# B6x register map
Vendor: XiaoMan; Series: B6 SOC; File version: 20260307
CPU: CM0+ r0p0, little endian, no MPU, no FPU, 2 interrupt priority bits
Registers are 32-bit, read-write, reset 0x0 unless marked. A register's access mark holds for its fields unless they carry their own. Offsets are from the block's base; [hi:lo] are bit positions; 'fields as' and 'values as' point back to an identical list.

## UART1
Base 0x40023000
Same registers: UART2 0x40024000
0x00 RBR — Receiver Buffer Register
0x04 TBR — Transmit Buffer Register
0x08 BRR — Baud rate register
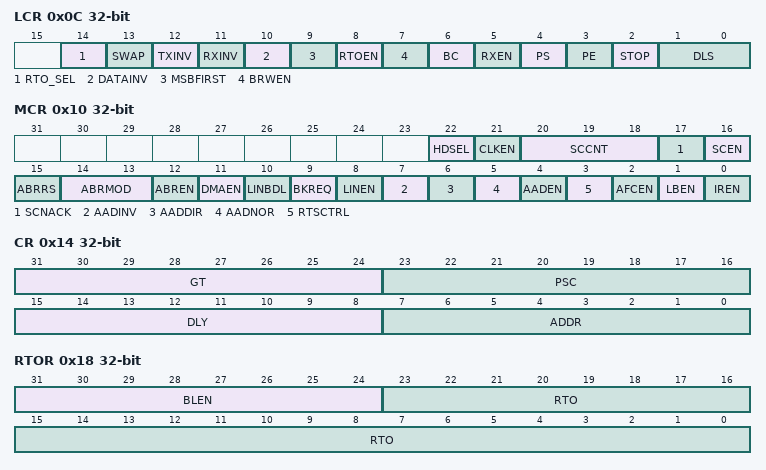
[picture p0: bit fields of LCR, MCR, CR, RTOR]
0x0C LCR — Line control register.
  [14] RTO_SEL — receiver timeout mode select: 0:CPU, 1:DMA
  [13] SWAP — Swap TX/RX pins
  [12] TXINV — TX pin active level inversion
  [11] RXINV — RX pin active level inversion
  [10] DATAINV — Binary data inversion
  [9] MSBFIRST — Most significant bit first
  [8] RTOEN — Receiver timeout enable
  [7] BRWEN — Baud rate register write enable
  [6] BC — Break control bit
  [5] RXEN — Receive enable
  [4] PS — Parity bit selection
  [3] PE — Parity bit enable
  [2] STOP — Stop bit
  [1:0] DLS — Data length selection
0x10 MCR — Mode control register
  [22] HDSEL — Half-duplex selection.
  [21] CLKEN — Clock enable.
  [20:18] SCCNT — Smartcard auto-retry count.
  [17] SCNACK — Smartcard NACK enable.
  [16] SCEN — Smartcard mode enable.
  [15] ABRRS — Auto baud rate detection restart.
  [14:13] ABRMOD — Auto baud rate mode.
  [12] ABREN — Auto baud rate enable.
  [11] DMAEN — DMA enable.
  [10] LINBDL
  [9] BKREQ — Break request.
  [8] LINEN — Lin mode enable.
  [7] AADINV — Automatic address detection invert.
  [6] AADDIR — Automatic address detection control enable.
  [5] AADNOR — Automatic address detection normal mode enable.
  [4] AADEN — Automatic address detection operation mode enable.
  [3] RTSCTRL — RTSn set control bit.
  [2] AFCEN — Auto flow control enable.
  [1] LBEN — LoopBack enable.
  [0] IREN — IrDA mode enable.
0x14 CR — Control register.
  [31:24] GT — Guard time value.
  [23:16] PSC — Prescaler value.
  [15:8] DLY — Delay value.
  [7:0] ADDR — Address match value.
0x18 RTOR — Receive timeout register.
  [31:24] BLEN — Block length.
  [23:0] RTO — Receive timeout value.
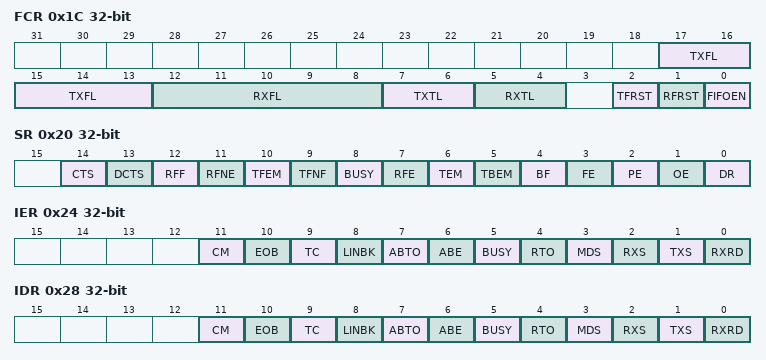
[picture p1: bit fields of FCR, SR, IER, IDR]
0x1C FCR — FIFO Control Register. Controls UART FIFO usage and modes.
  [17:13] TXFL — Transmit FIFO level.
  [12:8] RXFL — Receive FIFO level.
  [7:6] TXTL — Transmit FIFO trigger level.
  [5:4] RXTL — Receive FIFO trigger level. These two bits determine how many receiver UART FIFO characters must be written before an interrupt is activated.
    0=TRIGGER_LEVEL_0 (Trigger level 0 (1 character or 0x01).); 1=TRIGGER_LEVEL_1 (Trigger level 1 (4 characters or 0x04).); 2=TRIGGER_LEVEL_2 (Trigger level 2 (8 characters or 0x08).); 3=TRIGGER_LEVEL_3 (Trigger level 3 (14 characters or 0x0E).)
  [2] TFRST — Transmit FIFO reset.
    0=NO_IMPACT_ON_EITHER_ (No impact on either of UART FIFOs.); 1=CLEAR (Writing a logic 1 to FCR[2] will clear all bytes in UART TX FIFO, reset the pointer logic. This bit is self-clearing.)
  [1] RFRST — Receive FIFO reset.
  [0] FIFOEN — FIFO enable.
    0=DISABLED (UART FIFOs are disabled. Must not be used in the application.); 1=ENABLED (Active high enable for both UART RX and TX FIFOs and FCR[7:1] access. This bit must be set for proper UART operation. Any transition on this bit will automatically clear the UART FIFOs.)
0x20 SR — Status register
  [14] CTS — Clear to send status.
  [13] DCTS — Delta clear to send.
  [12] RFF — Receive FIFO full.
  [11] RFNE — Receive FIFO not empty.
  [10] TFEM — Transmit FIFO empty.
  [9] TFNF — Transmit FIFO not full.
  [8] BUSY — USART BUSY.
  [7] RFE — Receiver FIFO data error.
  [6] TEM — Transmitter empty.
  [5] TBEM — Transmit buffer register empty.
  [4] BF
  [3] FE — Framing error.
  [2] PE — Parity error.
  [1] OE — Overrun error.
  [0] DR — Data ready.
0x24 IER — Interrupt enable register.
  [11] CM — Character match Interrupt enable status.
  [10] EOB — End of block Interrupt enable status.
  [9] TC — Transmission complete Interrupt enable status.
  [8] LINBK — LIN break detection Interrupt enable status.
  [7] ABTO — Auto Baud Rate Timeout Interrupt enable status.
  [6] ABE — Auto Baud Rate End Interrupt enable status.
  [5] BUSY — Busy Detect Interrupt enable status.
  [4] RTO — Receiver timeout enable status.
  [3] MDS — Modem Status Interrupt enable status.
  [2] RXS — Receiver Line Status Interrupt enable status.
  [1] TXS — Transmit Empty Status Interrupt enable status.
  [0] RXRD — Receive Data available Interrupt enable status.
0x28 IDR — Interrupt disable register.
  fields as IER
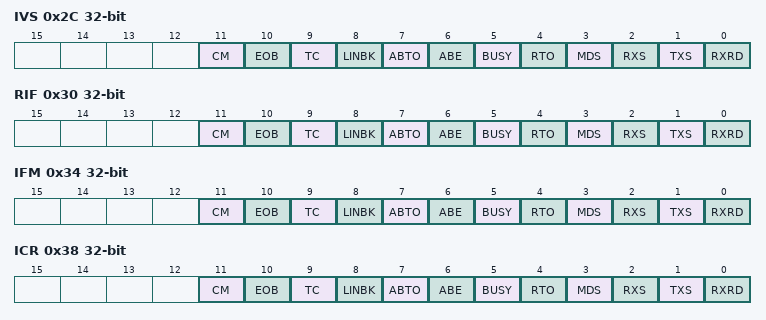
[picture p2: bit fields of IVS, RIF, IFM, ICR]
0x2C IVS — Interrupt valid status.
  fields as IER
0x30 RIF — Raw interrupt flag.
  fields as IER
0x34 IFM — Interrupt flag masked.
  fields as IER
0x38 ICR — Interrupt clear register.
  fields as IER
